AUTOSAR XML (schema 00048)
package /MICROSAR/BswM_swc
  8 x mode declaration group, all with category=EXPLICIT_ORDER:
    ESH_Mode: initial-mode=STARTUP, on-transition-value=5
      5 x mode:
        STARTUP: value=0
        RUN: value=1
        POSTRUN: value=2
        WAKEUP: value=3
        SHUTDOWN: value=4
    ESH_RunRequest: initial-mode=RELEASED, on-transition-value=2
      mode RELEASED: value=0
      mode REQUESTED: value=1
    SDC_SdEventHandlerState: initial-mode=SDC_EH_RELEASED, on-transition-value=2
      mode SDC_EH_RELEASED: value=0
      mode SDC_EH_REQUESTED: value=1
    SDC_SdClientServiceState: initial-mode=SDC_CLIENT_DOWN, on-transition-value=2
      mode SDC_CLIENT_DOWN: value=0
      mode SDC_CLIENT_AVAILABLE: value=1
    SDC_SdConsumedEventGroupState: initial-mode=SDC_CEG_DOWN, on-transition-value=2
      mode SDC_CEG_DOWN: value=0
      mode SDC_CEG_AVAILABLE: value=1
    SDC_SdServerServiceRequest: initial-mode=SDC_SERVER_DOWN, on-transition-value=2
      mode SDC_SERVER_DOWN: value=0
      mode SDC_SERVER_AVAILABE: value=1
    SDC_SdConsumedEventGroupRequest: initial-mode=SDC_CEG_RELEASED, on-transition-value=2
      mode SDC_CEG_RELEASED: value=0
      mode SDC_CEG_REQUESTED: value=1
    SDC_SdClientServiceRequest: initial-mode=SDC_CLIENT_RELEASED, on-transition-value=2
      mode SDC_CLIENT_RELEASED: value=0
      mode SDC_CLIENT_REQUESTED: value=1
  data type mapping set BswMMappingSet  # Contains Mapping for ModeDeclarations Groups which are provided by BswM.
    mode-request-type-maps:
      implementation-data-type=BswM_ESH_Mode, mode-group=ESH_Mode
      implementation-data-type=BswM_ESH_RunRequest, mode-group=ESH_RunRequest
      implementation-data-type=BswM_SDC_SdEventHandlerState, mode-group=SDC_SdEventHandlerState
      implementation-data-type=BswM_SDC_SdClientServiceState, mode-group=SDC_SdClientServiceState
      implementation-data-type=BswM_SDC_SdConsumedEventGroupState, mode-group=SDC_SdConsumedEventGroupState
      implementation-data-type=BswM_SDC_SdServerServiceRequest, mode-group=SDC_SdServerServiceRequest
      implementation-data-type=BswM_SDC_SdConsumedEventGroupRequest, mode-group=SDC_SdConsumedEventGroupRequest
      implementation-data-type=BswM_SDC_SdClientServiceRequest, mode-group=SDC_SdClientServiceRequest
package /MICROSAR/BswM_swc/DataTypes
  8 x impl type, all with category=TYPE_REFERENCE, range raw 0..255, implementation-data-type=uint8:
    BswM_ESH_Mode: compu {0=STARTUP, 1=RUN, 2=POSTRUN, 3=WAKEUP, 4=SHUTDOWN}  # Unique value for each user
    BswM_ESH_RunRequest: compu {0=RELEASED, 1=REQUESTED}  # Unique value for each user
    BswM_SDC_SdEventHandlerState: compu {0=SDC_EH_RELEASED, 1=SDC_EH_REQUESTED}  # Unique value for each user
    BswM_SDC_SdClientServiceState: compu {0=SDC_CLIENT_DOWN, 1=SDC_CLIENT_AVAILABLE}  # Unique value for each user
    BswM_SDC_SdConsumedEventGroupState: compu {0=SDC_CEG_DOWN, 1=SDC_CEG_AVAILABLE}  # Unique value for each user
    BswM_SDC_SdServerServiceRequest: compu {0=SDC_SERVER_DOWN, 1=SDC_SERVER_AVAILABE}  # Unique value for each user
    BswM_SDC_SdConsumedEventGroupRequest: compu {0=SDC_CEG_RELEASED, 1=SDC_CEG_REQUESTED}  # Unique value for each user
    BswM_SDC_SdClientServiceRequest: compu {0=SDC_CLIENT_RELEASED, 1=SDC_CLIENT_REQUESTED}  # Unique value for each user
package /MICROSAR/BswM_swc/Interfaces
  mode switch interface BswM_MSI_ESH_Mode: is-service=true, service-kind=BASIC-SOFTWARE-MODE-MANAGER
    mode group BswM_MDGP_ESH_Mode: type=ESH_Mode
  sender receiver interface BswM_SRI_BswM_MSI_ESH_Mode_BswM_MDGP_ESH_Mode: is-service=true, service-kind=BASIC-SOFTWARE-MODE-MANAGER
    data requestedMode: type=BswM_ESH_Mode
  mode switch interface BswM_MSI_ESH_RunRequest: is-service=true, service-kind=BASIC-SOFTWARE-MODE-MANAGER
    mode group BswM_MDGP_ESH_RunRequest: type=ESH_RunRequest
  sender receiver interface BswM_SRI_BswM_MSI_ESH_RunRequest_BswM_MDGP_ESH_RunRequest: is-service=true, service-kind=BASIC-SOFTWARE-MODE-MANAGER
    data requestedMode: type=BswM_ESH_RunRequest
  mode switch interface BswM_MSI_SDC_SdEventHandlerState: is-service=true, service-kind=BASIC-SOFTWARE-MODE-MANAGER
    mode group BswM_MDGP_SDC_SdEventHandlerState: type=SDC_SdEventHandlerState
  sender receiver interface BswM_SRI_BswM_MSI_SDC_SdEventHandlerState_BswM_MDGP_SDC_SdEventHandlerState: is-service=true, service-kind=BASIC-SOFTWARE-MODE-MANAGER
    data requestedMode: type=BswM_SDC_SdEventHandlerState
  mode switch interface BswM_MSI_SDC_SdClientServiceState: is-service=true, service-kind=BASIC-SOFTWARE-MODE-MANAGER
    mode group BswM_MDGP_SDC_SdClientServiceState: type=SDC_SdClientServiceState
  sender receiver interface BswM_SRI_BswM_MSI_SDC_SdClientServiceState_BswM_MDGP_SDC_SdClientServiceState: is-service=true, service-kind=BASIC-SOFTWARE-MODE-MANAGER
    data requestedMode: type=BswM_SDC_SdClientServiceState
  mode switch interface BswM_MSI_SDC_SdConsumedEventGroupState: is-service=true, service-kind=BASIC-SOFTWARE-MODE-MANAGER
    mode group BswM_MDGP_SDC_SdConsumedEventGroupState: type=SDC_SdConsumedEventGroupState
  sender receiver interface BswM_SRI_BswM_MSI_SDC_SdConsumedEventGroupState_BswM_MDGP_SDC_SdConsumedEventGroupState: is-service=true, service-kind=BASIC-SOFTWARE-MODE-MANAGER
    data requestedMode: type=BswM_SDC_SdConsumedEventGroupState
  mode switch interface BswM_MSI_SDC_SdServerServiceRequest: is-service=true, service-kind=BASIC-SOFTWARE-MODE-MANAGER
    mode group BswM_MDGP_SDC_SdServerServiceRequest: type=SDC_SdServerServiceRequest
  sender receiver interface BswM_SRI_BswM_MSI_SDC_SdServerServiceRequest_BswM_MDGP_SDC_SdServerServiceRequest: is-service=true, service-kind=BASIC-SOFTWARE-MODE-MANAGER
    data requestedMode: type=BswM_SDC_SdServerServiceRequest
  mode switch interface BswM_MSI_SDC_SdConsumedEventGroupRequest: is-service=true, service-kind=BASIC-SOFTWARE-MODE-MANAGER
    mode group BswM_MDGP_SDC_SdConsumedEventGroupRequest: type=SDC_SdConsumedEventGroupRequest
  sender receiver interface BswM_SRI_BswM_MSI_SDC_SdConsumedEventGroupRequest_BswM_MDGP_SDC_SdConsumedEventGroupRequest: is-service=true, service-kind=BASIC-SOFTWARE-MODE-MANAGER
    data requestedMode: type=BswM_SDC_SdConsumedEventGroupRequest
  mode switch interface BswM_MSI_SDC_SdClientServiceRequest: is-service=true, service-kind=BASIC-SOFTWARE-MODE-MANAGER
    mode group BswM_MDGP_SDC_SdClientServiceRequest: type=SDC_SdClientServiceRequest
  sender receiver interface BswM_SRI_BswM_MSI_SDC_SdClientServiceRequest_BswM_MDGP_SDC_SdClientServiceRequest: is-service=true, service-kind=BASIC-SOFTWARE-MODE-MANAGER
    data requestedMode: type=BswM_SDC_SdClientServiceRequest
package /MICROSAR/BswM_swc/ComponentTypes
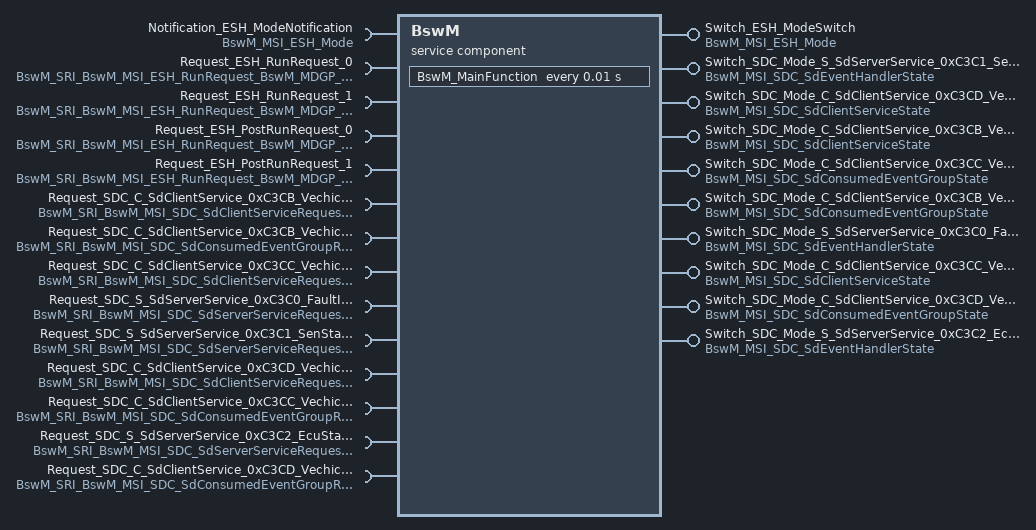
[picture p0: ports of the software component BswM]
  service sw component type BswM: category=SERVICE_COMPONENT
    provide port Switch_ESH_ModeSwitch: provided-interface=BswM_MSI_ESH_Mode
    5 x require port:
      Notification_ESH_ModeNotification: required-interface=BswM_MSI_ESH_Mode
      Request_ESH_RunRequest_0: nonqueued-receiver-com-spec{data-element=BswM_SRI_BswM_MSI_ESH_RunRequest_BswM_MDGP_ESH_RunRequest/requestedMode, handle-out-of-range-status=SILENT, init-value=RELEASED}, required-interface=BswM_SRI_BswM_MSI_ESH_RunRequest_BswM_MDGP_ESH_RunRequest
      Request_ESH_RunRequest_1: nonqueued-receiver-com-spec{data-element=BswM_SRI_BswM_MSI_ESH_RunRequest_BswM_MDGP_ESH_RunRequest/requestedMode, handle-out-of-range-status=SILENT, init-value=RELEASED}, required-interface=BswM_SRI_BswM_MSI_ESH_RunRequest_BswM_MDGP_ESH_RunRequest
      Request_ESH_PostRunRequest_0: nonqueued-receiver-com-spec{data-element=BswM_SRI_BswM_MSI_ESH_RunRequest_BswM_MDGP_ESH_RunRequest/requestedMode, handle-out-of-range-status=SILENT, init-value=RELEASED}, required-interface=BswM_SRI_BswM_MSI_ESH_RunRequest_BswM_MDGP_ESH_RunRequest
      Request_ESH_PostRunRequest_1: nonqueued-receiver-com-spec{data-element=BswM_SRI_BswM_MSI_ESH_RunRequest_BswM_MDGP_ESH_RunRequest/requestedMode, handle-out-of-range-status=SILENT, init-value=RELEASED}, required-interface=BswM_SRI_BswM_MSI_ESH_RunRequest_BswM_MDGP_ESH_RunRequest
    9 x provide port:
      Switch_SDC_Mode_S_SdServerService_0xC3C1_SenState_EH_SdEventHandler_0xC3C1_SenState: provided-interface=BswM_MSI_SDC_SdEventHandlerState
      Switch_SDC_Mode_C_SdClientService_0xC3CD_VechicleInfo: provided-interface=BswM_MSI_SDC_SdClientServiceState
      Switch_SDC_Mode_C_SdClientService_0xC3CB_VechicleSpeed: provided-interface=BswM_MSI_SDC_SdClientServiceState
      Switch_SDC_Mode_C_SdClientService_0xC3CC_VechicleStatus_CEG_SdConsumedEventGroup_0xC3CC_VechicleStatus: provided-interface=BswM_MSI_SDC_SdConsumedEventGroupState
      Switch_SDC_Mode_C_SdClientService_0xC3CB_VechicleSpeed_CEG_SdConsumedEventGroup_0xC3CB_VechicleSpeed: provided-interface=BswM_MSI_SDC_SdConsumedEventGroupState
      Switch_SDC_Mode_S_SdServerService_0xC3C0_FaultInfo_EH_SdEventHandler_0xC3C0_FaultInfo: provided-interface=BswM_MSI_SDC_SdEventHandlerState
      Switch_SDC_Mode_C_SdClientService_0xC3CC_VechicleStatus: provided-interface=BswM_MSI_SDC_SdClientServiceState
      Switch_SDC_Mode_C_SdClientService_0xC3CD_VechicleInfo_CEG_SdConsumedEventGroup_0xC3CD_VechicleInfo: provided-interface=BswM_MSI_SDC_SdConsumedEventGroupState
      Switch_SDC_Mode_S_SdServerService_0xC3C2_EcuState_EH_SdEventHandler_0xC3C2_EcuState: provided-interface=BswM_MSI_SDC_SdEventHandlerState
    9 x require port:
      Request_SDC_C_SdClientService_0xC3CB_VechicleSpeed: nonqueued-receiver-com-spec{data-element=BswM_SRI_BswM_MSI_SDC_SdClientServiceRequest_BswM_MDGP_SDC_SdClientServiceRequest/requestedMode, handle-out-of-range-status=SILENT, init-value=SDC_CLIENT_REQUESTED}, required-interface=BswM_SRI_BswM_MSI_SDC_SdClientServiceRequest_BswM_MDGP_SDC_SdClientServiceRequest
      Request_SDC_C_SdClientService_0xC3CB_VechicleSpeed_CEG_SdConsumedEventGroup_0xC3CB_VechicleSpeed: nonqueued-receiver-com-spec{data-element=BswM_SRI_BswM_MSI_SDC_SdConsumedEventGroupRequest_BswM_MDGP_SDC_SdConsumedEventGroupRequest/requestedMode, handle-out-of-range-status=SILENT, init-value=SDC_CEG_REQUESTED}, required-interface=BswM_SRI_BswM_MSI_SDC_SdConsumedEventGroupRequest_BswM_MDGP_SDC_SdConsumedEventGroupRequest
      Request_SDC_C_SdClientService_0xC3CC_VechicleStatus: nonqueued-receiver-com-spec{data-element=BswM_SRI_BswM_MSI_SDC_SdClientServiceRequest_BswM_MDGP_SDC_SdClientServiceRequest/requestedMode, handle-out-of-range-status=SILENT, init-value=SDC_CLIENT_REQUESTED}, required-interface=BswM_SRI_BswM_MSI_SDC_SdClientServiceRequest_BswM_MDGP_SDC_SdClientServiceRequest
      Request_SDC_S_SdServerService_0xC3C0_FaultInfo: nonqueued-receiver-com-spec{data-element=BswM_SRI_BswM_MSI_SDC_SdServerServiceRequest_BswM_MDGP_SDC_SdServerServiceRequest/requestedMode, handle-out-of-range-status=SILENT, init-value=SDC_SERVER_AVAILABE}, required-interface=BswM_SRI_BswM_MSI_SDC_SdServerServiceRequest_BswM_MDGP_SDC_SdServerServiceRequest
      Request_SDC_S_SdServerService_0xC3C1_SenState: nonqueued-receiver-com-spec{data-element=BswM_SRI_BswM_MSI_SDC_SdServerServiceRequest_BswM_MDGP_SDC_SdServerServiceRequest/requestedMode, handle-out-of-range-status=SILENT, init-value=SDC_SERVER_AVAILABE}, required-interface=BswM_SRI_BswM_MSI_SDC_SdServerServiceRequest_BswM_MDGP_SDC_SdServerServiceRequest
      Request_SDC_C_SdClientService_0xC3CD_VechicleInfo: nonqueued-receiver-com-spec{data-element=BswM_SRI_BswM_MSI_SDC_SdClientServiceRequest_BswM_MDGP_SDC_SdClientServiceRequest/requestedMode, handle-out-of-range-status=SILENT, init-value=SDC_CLIENT_RELEASED}, required-interface=BswM_SRI_BswM_MSI_SDC_SdClientServiceRequest_BswM_MDGP_SDC_SdClientServiceRequest
      Request_SDC_C_SdClientService_0xC3CC_VechicleStatus_CEG_SdConsumedEventGroup_0xC3CC_VechicleStatus: nonqueued-receiver-com-spec{data-element=BswM_SRI_BswM_MSI_SDC_SdConsumedEventGroupRequest_BswM_MDGP_SDC_SdConsumedEventGroupRequest/requestedMode, handle-out-of-range-status=SILENT, init-value=SDC_CEG_REQUESTED}, required-interface=BswM_SRI_BswM_MSI_SDC_SdConsumedEventGroupRequest_BswM_MDGP_SDC_SdConsumedEventGroupRequest
      Request_SDC_S_SdServerService_0xC3C2_EcuState: nonqueued-receiver-com-spec{data-element=BswM_SRI_BswM_MSI_SDC_SdServerServiceRequest_BswM_MDGP_SDC_SdServerServiceRequest/requestedMode, handle-out-of-range-status=SILENT, init-value=SDC_SERVER_AVAILABE}, required-interface=BswM_SRI_BswM_MSI_SDC_SdServerServiceRequest_BswM_MDGP_SDC_SdServerServiceRequest
      Request_SDC_C_SdClientService_0xC3CD_VechicleInfo_CEG_SdConsumedEventGroup_0xC3CD_VechicleInfo: nonqueued-receiver-com-spec{data-element=BswM_SRI_BswM_MSI_SDC_SdConsumedEventGroupRequest_BswM_MDGP_SDC_SdConsumedEventGroupRequest/requestedMode, handle-out-of-range-status=SILENT, init-value=SDC_CEG_REQUESTED}, required-interface=BswM_SRI_BswM_MSI_SDC_SdConsumedEventGroupRequest_BswM_MDGP_SDC_SdConsumedEventGroupRequest
    behavior BswMInternalBehavior: data-type-mapping=BswMMappingSet, handle-termination-and-restart=NO-SUPPORT, included-data-type-set=data-type=[BswM_ESH_Mode, BswM_ESH_RunRequest, BswM_SDC_SdEventHandlerState, BswM_SDC_SdClientServiceState, BswM_SDC_SdConsumedEventGroupState, BswM_SDC_SdServerServiceRequest, BswM_SDC_SdConsumedEventGroupRequest, BswM_SDC_SdClientServiceRequest]
      timing event Timer_BswM_MainFunction: start-on-event=BswM_MainFunction, period=0.01
      port-api-options:
        enable-take-address=true, indirect-api=false, port=Switch_ESH_ModeSwitch
        enable-take-address=true, indirect-api=false, port=Switch_SDC_Mode_S_SdServerService_0xC3C1_SenState_EH_SdEventHandler_0xC3C1_SenState
        enable-take-address=true, indirect-api=false, port=Switch_SDC_Mode_C_SdClientService_0xC3CD_VechicleInfo
        enable-take-address=true, indirect-api=false, port=Switch_SDC_Mode_C_SdClientService_0xC3CB_VechicleSpeed
        enable-take-address=true, indirect-api=false, port=Switch_SDC_Mode_C_SdClientService_0xC3CC_VechicleStatus_CEG_SdConsumedEventGroup_0xC3CC_VechicleStatus
        enable-take-address=true, indirect-api=false, port=Switch_SDC_Mode_C_SdClientService_0xC3CB_VechicleSpeed_CEG_SdConsumedEventGroup_0xC3CB_VechicleSpeed
        enable-take-address=true, indirect-api=false, port=Switch_SDC_Mode_S_SdServerService_0xC3C0_FaultInfo_EH_SdEventHandler_0xC3C0_FaultInfo
        enable-take-address=true, indirect-api=false, port=Switch_SDC_Mode_C_SdClientService_0xC3CC_VechicleStatus
        enable-take-address=true, indirect-api=false, port=Switch_SDC_Mode_C_SdClientService_0xC3CD_VechicleInfo_CEG_SdConsumedEventGroup_0xC3CD_VechicleInfo
        enable-take-address=true, indirect-api=false, port=Switch_SDC_Mode_S_SdServerService_0xC3C2_EcuState_EH_SdEventHandler_0xC3C2_EcuState
        enable-take-address=true, indirect-api=false, port=Notification_ESH_ModeNotification
        enable-take-address=true, indirect-api=false, port=Request_ESH_RunRequest_0
        enable-take-address=true, indirect-api=false, port=Request_ESH_RunRequest_1
        enable-take-address=true, indirect-api=false, port=Request_ESH_PostRunRequest_0
        enable-take-address=true, indirect-api=false, port=Request_ESH_PostRunRequest_1
        enable-take-address=true, indirect-api=false, port=Request_SDC_C_SdClientService_0xC3CB_VechicleSpeed
        enable-take-address=true, indirect-api=false, port=Request_SDC_C_SdClientService_0xC3CB_VechicleSpeed_CEG_SdConsumedEventGroup_0xC3CB_VechicleSpeed
        enable-take-address=true, indirect-api=false, port=Request_SDC_C_SdClientService_0xC3CC_VechicleStatus
        enable-take-address=true, indirect-api=false, port=Request_SDC_S_SdServerService_0xC3C0_FaultInfo
        enable-take-address=true, indirect-api=false, port=Request_SDC_S_SdServerService_0xC3C1_SenState
        enable-take-address=true, indirect-api=false, port=Request_SDC_C_SdClientService_0xC3CD_VechicleInfo
        enable-take-address=true, indirect-api=false, port=Request_SDC_C_SdClientService_0xC3CC_VechicleStatus_CEG_SdConsumedEventGroup_0xC3CC_VechicleStatus
        enable-take-address=true, indirect-api=false, port=Request_SDC_S_SdServerService_0xC3C2_EcuState
        enable-take-address=true, indirect-api=false, port=Request_SDC_C_SdClientService_0xC3CD_VechicleInfo_CEG_SdConsumedEventGroup_0xC3CD_VechicleInfo
      runnable BswM_MainFunction: mode-access-point=Notification_ESH_ModeNotification.BswM_MDGP_ESH_Mode
        data-receive-point-by-arguments:
          13 x access:
            DataReceivePointBswM_MainFunction_Request_ESH_RunRequest_0_requestedMode: accessed-variable=Request_ESH_RunRequest_0.requestedMode
            DataReceivePointBswM_MainFunction_Request_ESH_RunRequest_1_requestedMode: accessed-variable=Request_ESH_RunRequest_1.requestedMode
            DataReceivePointBswM_MainFunction_Request_ESH_PostRunRequest_0_requestedMode: accessed-variable=Request_ESH_PostRunRequest_0.requestedMode
            DataReceivePointBswM_MainFunction_Request_ESH_PostRunRequest_1_requestedMode: accessed-variable=Request_ESH_PostRunRequest_1.requestedMode
            DataReceivePointBswM_MainFunction_Request_SDC_C_SdClientService_0xC3CB_VechicleSpeed_requestedMode: accessed-variable=Request_SDC_C_SdClientService_0xC3CB_VechicleSpeed.requestedMode
            DataReceivePointBswM_MainFunction_Request_SDC_C_SdClientService_0xC3CB_VechicleSpeed_CEG_SdConsumedEventGroup_0xC3CB_Ve_a6da65d5: accessed-variable=Request_SDC_C_SdClientService_0xC3CB_VechicleSpeed_CEG_SdConsumedEventGroup_0xC3CB_VechicleSpeed.requestedMode
            DataReceivePointBswM_MainFunction_Request_SDC_C_SdClientService_0xC3CC_VechicleStatus_requestedMode: accessed-variable=Request_SDC_C_SdClientService_0xC3CC_VechicleStatus.requestedMode
            DataReceivePointBswM_MainFunction_Request_SDC_S_SdServerService_0xC3C0_FaultInfo_requestedMode: accessed-variable=Request_SDC_S_SdServerService_0xC3C0_FaultInfo.requestedMode
            DataReceivePointBswM_MainFunction_Request_SDC_S_SdServerService_0xC3C1_SenState_requestedMode: accessed-variable=Request_SDC_S_SdServerService_0xC3C1_SenState.requestedMode
            DataReceivePointBswM_MainFunction_Request_SDC_C_SdClientService_0xC3CD_VechicleInfo_requestedMode: accessed-variable=Request_SDC_C_SdClientService_0xC3CD_VechicleInfo.requestedMode
            DataReceivePointBswM_MainFunction_Request_SDC_C_SdClientService_0xC3CC_VechicleStatus_CEG_SdConsumedEventGroup_0xC3CC_V_ce59269e: accessed-variable=Request_SDC_C_SdClientService_0xC3CC_VechicleStatus_CEG_SdConsumedEventGroup_0xC3CC_VechicleStatus.requestedMode
            DataReceivePointBswM_MainFunction_Request_SDC_S_SdServerService_0xC3C2_EcuState_requestedMode: accessed-variable=Request_SDC_S_SdServerService_0xC3C2_EcuState.requestedMode
            DataReceivePointBswM_MainFunction_Request_SDC_C_SdClientService_0xC3CD_VechicleInfo_CEG_SdConsumedEventGroup_0xC3CD_Vec_439e99ae: accessed-variable=Request_SDC_C_SdClientService_0xC3CD_VechicleInfo_CEG_SdConsumedEventGroup_0xC3CD_VechicleInfo.requestedMode
        10 x mode switch point:
          ModeSwitchPointBswM_MainFunction_Switch_ESH_ModeSwitch_BswM_MDGP_ESH_Mode: mode-group=Switch_ESH_ModeSwitch.BswM_MDGP_ESH_Mode
          ModeSwitchPointBswM_MainFunction_Switch_SDC_Mode_S_SdServerService_0xC3C1_SenState_EH_SdEventHandler_0xC3C1_SenState_Bs_4db5fb0b: mode-group=Switch_SDC_Mode_S_SdServerService_0xC3C1_SenState_EH_SdEventHandler_0xC3C1_SenState.BswM_MDGP_SDC_SdEventHandlerState
          ModeSwitchPointBswM_MainFunction_Switch_SDC_Mode_C_SdClientService_0xC3CD_VechicleInfo_BswM_MDGP_SDC_SdClientServiceState: mode-group=Switch_SDC_Mode_C_SdClientService_0xC3CD_VechicleInfo.BswM_MDGP_SDC_SdClientServiceState
          ModeSwitchPointBswM_MainFunction_Switch_SDC_Mode_C_SdClientService_0xC3CB_VechicleSpeed_BswM_MDGP_SDC_SdClientServiceState: mode-group=Switch_SDC_Mode_C_SdClientService_0xC3CB_VechicleSpeed.BswM_MDGP_SDC_SdClientServiceState
          ModeSwitchPointBswM_MainFunction_Switch_SDC_Mode_C_SdClientService_0xC3CC_VechicleStatus_CEG_SdConsumedEventGroup_0xC3C_d743fa2f: mode-group=Switch_SDC_Mode_C_SdClientService_0xC3CC_VechicleStatus_CEG_SdConsumedEventGroup_0xC3CC_VechicleStatus.BswM_MDGP_SDC_SdConsumedEventGroupState
          ModeSwitchPointBswM_MainFunction_Switch_SDC_Mode_C_SdClientService_0xC3CB_VechicleSpeed_CEG_SdConsumedEventGroup_0xC3CB_5fdfd462: mode-group=Switch_SDC_Mode_C_SdClientService_0xC3CB_VechicleSpeed_CEG_SdConsumedEventGroup_0xC3CB_VechicleSpeed.BswM_MDGP_SDC_SdConsumedEventGroupState
          ModeSwitchPointBswM_MainFunction_Switch_SDC_Mode_S_SdServerService_0xC3C0_FaultInfo_EH_SdEventHandler_0xC3C0_FaultInfo_92498af4: mode-group=Switch_SDC_Mode_S_SdServerService_0xC3C0_FaultInfo_EH_SdEventHandler_0xC3C0_FaultInfo.BswM_MDGP_SDC_SdEventHandlerState
          ModeSwitchPointBswM_MainFunction_Switch_SDC_Mode_C_SdClientService_0xC3CC_VechicleStatus_BswM_MDGP_SDC_SdClientServiceState: mode-group=Switch_SDC_Mode_C_SdClientService_0xC3CC_VechicleStatus.BswM_MDGP_SDC_SdClientServiceState
          ModeSwitchPointBswM_MainFunction_Switch_SDC_Mode_C_SdClientService_0xC3CD_VechicleInfo_CEG_SdConsumedEventGroup_0xC3CD_1704146a: mode-group=Switch_SDC_Mode_C_SdClientService_0xC3CD_VechicleInfo_CEG_SdConsumedEventGroup_0xC3CD_VechicleInfo.BswM_MDGP_SDC_SdConsumedEventGroupState
          ModeSwitchPointBswM_MainFunction_Switch_SDC_Mode_S_SdServerService_0xC3C2_EcuState_EH_SdEventHandler_0xC3C2_EcuState_Bs_4090b569: mode-group=Switch_SDC_Mode_S_SdServerService_0xC3C2_EcuState_EH_SdEventHandler_0xC3C2_EcuState.BswM_MDGP_SDC_SdEventHandlerState
  swc implementation BswMImplementation: programming-language=C, behavior=BswMInternalBehavior
